VERSION ""

NS_ :

BS_:

BU_: XXX

BO_ 336 NEW_MSG_1: 8 XXX
 SG_ NEW_SIGNAL_1 : 32|8@1+ (1,0) [0|255] "" XXX

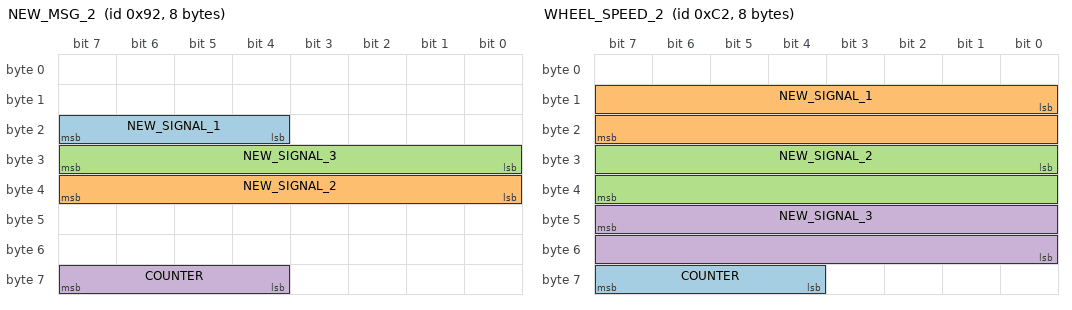
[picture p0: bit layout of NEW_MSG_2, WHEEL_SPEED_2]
BO_ 146 NEW_MSG_2: 8 XXX
 SG_ NEW_SIGNAL_1 : 23|4@0+ (1,0) [0|15] "" XXX
 SG_ NEW_SIGNAL_2 : 39|8@0+ (1,0) [0|255] "" XXX
 SG_ NEW_SIGNAL_3 : 31|8@0+ (1,0) [0|255] "" XXX
 SG_ COUNTER : 63|4@0+ (1,0) [0|15] "" XXX

BO_ 194 WHEEL_SPEED_2: 8 XXX
 SG_ COUNTER : 63|4@0+ (1,0) [0|15] "" XXX
 SG_ NEW_SIGNAL_1 : 8|16@1+ (1,0) [0|65535] "" XXX
 SG_ NEW_SIGNAL_2 : 24|16@1+ (1,0) [0|65535] "" XXX
 SG_ NEW_SIGNAL_3 : 47|16@0+ (1,0) [0|65535] "" XXX

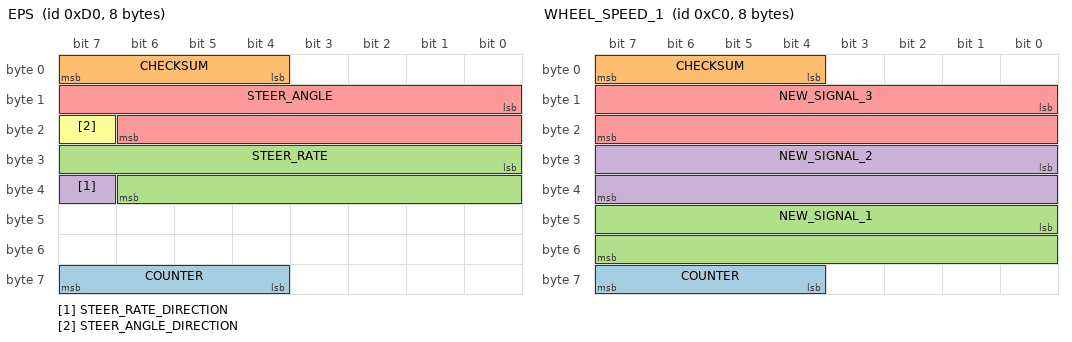
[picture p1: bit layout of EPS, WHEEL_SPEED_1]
BO_ 208 EPS: 8 XXX
 SG_ COUNTER : 63|4@0+ (1,0) [0|15] "" XXX
 SG_ CHECKSUM : 7|4@0+ (1,0) [0|15] "" XXX
 SG_ STEER_RATE : 24|15@1+ (1,0) [0|65535] "" XXX
 SG_ STEER_RATE_DIRECTION : 39|1@0+ (1,0) [0|1] "" XXX
 SG_ STEER_ANGLE : 8|15@1+ (1,0) [0|65535] "" XXX
 SG_ STEER_ANGLE_DIRECTION : 23|1@0+ (1,0) [0|1] "" XXX

BO_ 144 NEW_MSG_5: 8 XXX
 SG_ NEW_SIGNAL_3 : 7|20@0+ (1,0) [0|16383] "" XXX
 SG_ NEW_SIGNAL_1 : 24|20@1+ (1,1) [0|63] "" XXX

BO_ 192 WHEEL_SPEED_1: 8 XXX
 SG_ COUNTER : 63|4@0+ (1,0) [0|15] "" XXX
 SG_ CHECKSUM : 7|4@0+ (1,0) [0|15] "" XXX
 SG_ NEW_SIGNAL_1 : 40|16@1+ (1,0) [0|65535] "" XXX
 SG_ NEW_SIGNAL_2 : 24|16@1+ (1,0) [0|65535] "" XXX
 SG_ NEW_SIGNAL_3 : 8|16@1+ (1,0) [0|65535] "" XXX
